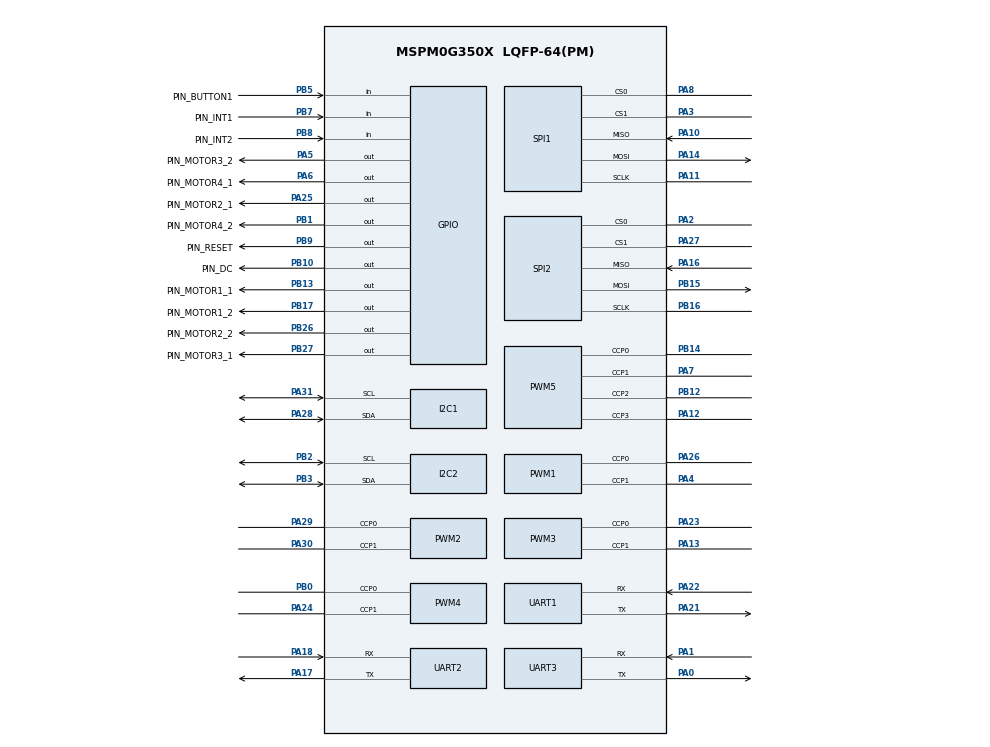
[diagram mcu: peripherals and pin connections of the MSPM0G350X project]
/**
 * @cliArgs --device "MSPM0G350X" --part "Default" --package "LQFP-64(PM)" --product "mspm0_sdk@2.03.00.07"
 * @versions {"tool":"1.22.0+3893"}
 */
scripting.excludeFromBuild("Event.dot");

/**
 * Import the modules used in this configuration.
 */
const ADC12         = scripting.addModule("/ti/driverlib/ADC12", {}, false);
const ADC121        = ADC12.addInstance();
const DMA           = scripting.addModule("/ti/driverlib/DMA");
const GPIO          = scripting.addModule("/ti/driverlib/GPIO", {}, false);
const GPIO1         = GPIO.addInstance();
const GPIO2         = GPIO.addInstance();
const GPIO3         = GPIO.addInstance();
const GPIO4         = GPIO.addInstance();
const GPIO5         = GPIO.addInstance();
const I2C           = scripting.addModule("/ti/driverlib/I2C", {}, false);
const I2C1          = I2C.addInstance();
const I2C2          = I2C.addInstance();
const PWM           = scripting.addModule("/ti/driverlib/PWM", {}, false);
const PWM1          = PWM.addInstance();
const PWM2          = PWM.addInstance();
const PWM3          = PWM.addInstance();
const PWM4          = PWM.addInstance();
const PWM5          = PWM.addInstance();
const RTC           = scripting.addModule("/ti/driverlib/RTC");
const SPI           = scripting.addModule("/ti/driverlib/SPI", {}, false);
const SPI1          = SPI.addInstance();
const SPI2          = SPI.addInstance();
const SYSCTL        = scripting.addModule("/ti/driverlib/SYSCTL");
const SYSTICK       = scripting.addModule("/ti/driverlib/SYSTICK");
const TIMER         = scripting.addModule("/ti/driverlib/TIMER", {}, false);
const TIMER1        = TIMER.addInstance();
const UART          = scripting.addModule("/ti/driverlib/UART", {}, false);
const UART1         = UART.addInstance();
const UART2         = UART.addInstance();
const UART3         = UART.addInstance();
const ProjectConfig = scripting.addModule("/ti/project_config/ProjectConfig");

/**
 * Write custom configuration values to the imported modules.
 */
ADC121.$name                      = "ADC12_0";
ADC121.peripheral.$assign         = "ADC1";
ADC121.peripheral.adcPin0.$assign = "PA15";
ADC121.adcPin0Config.$name        = "ti_driverlib_gpio_GPIOPinGeneric32";

const Board = scripting.addModule("/ti/driverlib/Board", {}, false);

GPIO1.$name                               = "GPIO_GRP_ENCODER";
GPIO1.associatedPins.create(8);
GPIO1.associatedPins[0].direction         = "INPUT";
GPIO1.associatedPins[0].ioStructure       = "SD";
GPIO1.associatedPins[0].assignedPort      = "PORTB";
GPIO1.associatedPins[0].interruptEn       = true;
GPIO1.associatedPins[0].interruptPriority = "2";
GPIO1.associatedPins[0].polarity          = "RISE_FALL";
GPIO1.associatedPins[0].$name             = "PIN_MOTOR1_A";
GPIO1.associatedPins[1].direction         = "INPUT";
GPIO1.associatedPins[1].ioStructure       = "SD";
GPIO1.associatedPins[1].assignedPort      = "PORTB";
GPIO1.associatedPins[1].interruptEn       = true;
GPIO1.associatedPins[1].polarity          = "RISE_FALL";
GPIO1.associatedPins[1].interruptPriority = "2";
GPIO1.associatedPins[1].$name             = "PIN_MOTOR1_B";
GPIO1.associatedPins[2].direction         = "INPUT";
GPIO1.associatedPins[2].ioStructure       = "SD";
GPIO1.associatedPins[2].assignedPort      = "PORTB";
GPIO1.associatedPins[2].interruptEn       = true;
GPIO1.associatedPins[2].interruptPriority = "2";
GPIO1.associatedPins[2].polarity          = "RISE_FALL";
GPIO1.associatedPins[2].$name             = "PIN_MOTOR2_A";
GPIO1.associatedPins[3].direction         = "INPUT";
GPIO1.associatedPins[3].ioStructure       = "SD";
GPIO1.associatedPins[3].interruptEn       = true;
GPIO1.associatedPins[3].interruptPriority = "2";
GPIO1.associatedPins[3].polarity          = "RISE_FALL";
GPIO1.associatedPins[3].assignedPort      = "PORTB";
GPIO1.associatedPins[3].$name             = "PIN_MOTOR2_B";
GPIO1.associatedPins[4].direction         = "INPUT";
GPIO1.associatedPins[4].ioStructure       = "SD";
GPIO1.associatedPins[4].interruptEn       = true;
GPIO1.associatedPins[4].interruptPriority = "2";
GPIO1.associatedPins[4].polarity          = "RISE_FALL";
GPIO1.associatedPins[4].assignedPort      = "PORTB";
GPIO1.associatedPins[4].$name             = "PIN_MOTOR3_A";
GPIO1.associatedPins[5].direction         = "INPUT";
GPIO1.associatedPins[5].ioStructure       = "SD";
GPIO1.associatedPins[5].interruptEn       = true;
GPIO1.associatedPins[5].polarity          = "RISE_FALL";
GPIO1.associatedPins[5].assignedPort      = "PORTB";
GPIO1.associatedPins[5].$name             = "PIN_MOTOR3_B";
GPIO1.associatedPins[6].direction         = "INPUT";
GPIO1.associatedPins[6].ioStructure       = "SD";
GPIO1.associatedPins[6].assignedPort      = "PORTB";
GPIO1.associatedPins[6].interruptEn       = true;
GPIO1.associatedPins[6].polarity          = "RISE_FALL";
GPIO1.associatedPins[6].$name             = "PIN_MOTOR4_A";
GPIO1.associatedPins[7].direction         = "INPUT";
GPIO1.associatedPins[7].ioStructure       = "SD";
GPIO1.associatedPins[7].assignedPort      = "PORTB";
GPIO1.associatedPins[7].interruptEn       = true;
GPIO1.associatedPins[7].polarity          = "RISE_FALL";
GPIO1.associatedPins[7].interruptPriority = "2";
GPIO1.associatedPins[7].$name             = "PIN_MOTOR4_B";

GPIO2.$name                          = "GPIO_GRP_MCTRL";
GPIO2.associatedPins.create(8);
GPIO2.associatedPins[0].ioStructure  = "SD";
GPIO2.associatedPins[0].initialValue = "SET";
GPIO2.associatedPins[0].$name        = "PIN_MOTOR1_1";
GPIO2.associatedPins[0].pin.$assign  = "PB13";
GPIO2.associatedPins[1].ioStructure  = "SD";
GPIO2.associatedPins[1].initialValue = "SET";
GPIO2.associatedPins[1].$name        = "PIN_MOTOR1_2";
GPIO2.associatedPins[1].pin.$assign  = "PB17";
GPIO2.associatedPins[2].initialValue = "SET";
GPIO2.associatedPins[2].$name        = "PIN_MOTOR2_1";
GPIO2.associatedPins[2].pin.$assign  = "PA25";
GPIO2.associatedPins[3].initialValue = "SET";
GPIO2.associatedPins[3].$name        = "PIN_MOTOR2_2";
GPIO2.associatedPins[3].pin.$assign  = "PB26";
GPIO2.associatedPins[4].initialValue = "SET";
GPIO2.associatedPins[4].$name        = "PIN_MOTOR3_1";
GPIO2.associatedPins[4].pin.$assign  = "PB27";
GPIO2.associatedPins[5].initialValue = "SET";
GPIO2.associatedPins[5].$name        = "PIN_MOTOR3_2";
GPIO2.associatedPins[5].pin.$assign  = "PA5";
GPIO2.associatedPins[6].initialValue = "SET";
GPIO2.associatedPins[6].$name        = "PIN_MOTOR4_1";
GPIO2.associatedPins[6].pin.$assign  = "PA6";
GPIO2.associatedPins[7].initialValue = "SET";
GPIO2.associatedPins[7].$name        = "PIN_MOTOR4_2";
GPIO2.associatedPins[7].pin.$assign  = "PB1";

GPIO3.$name                               = "GPIO_GRP_BUTTON";
GPIO3.associatedPins[0].direction         = "INPUT";
GPIO3.associatedPins[0].ioStructure       = "SD";
GPIO3.associatedPins[0].interruptEn       = true;
GPIO3.associatedPins[0].interruptPriority = "2";
GPIO3.associatedPins[0].polarity          = "FALL";
GPIO3.associatedPins[0].$name             = "PIN_BUTTON1";
GPIO3.associatedPins[0].pin.$assign       = "PB5";

GPIO4.$name                               = "GPIO_GRP_IMU_INT";
GPIO4.associatedPins.create(2);
GPIO4.associatedPins[0].$name             = "PIN_INT1";
GPIO4.associatedPins[0].direction         = "INPUT";
GPIO4.associatedPins[0].ioStructure       = "SD";
GPIO4.associatedPins[0].interruptEn       = true;
GPIO4.associatedPins[0].interruptPriority = "1";
GPIO4.associatedPins[0].polarity          = "RISE";
GPIO4.associatedPins[0].pin.$assign       = "PB7";
GPIO4.associatedPins[1].$name             = "PIN_INT2";
GPIO4.associatedPins[1].direction         = "INPUT";
GPIO4.associatedPins[1].ioStructure       = "SD";
GPIO4.associatedPins[1].interruptEn       = true;
GPIO4.associatedPins[1].interruptPriority = "1";
GPIO4.associatedPins[1].polarity          = "RISE";
GPIO4.associatedPins[1].pin.$assign       = "PB8";

GPIO5.$name                          = "GPIO_GRP_OLED";
GPIO5.associatedPins.create(2);
GPIO5.associatedPins[0].initialValue = "SET";
GPIO5.associatedPins[0].ioStructure  = "SD";
GPIO5.associatedPins[0].$name        = "PIN_RESET";
GPIO5.associatedPins[0].pin.$assign  = "PB9";
GPIO5.associatedPins[1].$name        = "PIN_DC";
GPIO5.associatedPins[1].initialValue = "SET";
GPIO5.associatedPins[1].ioStructure  = "SD";
GPIO5.associatedPins[1].pin.$assign  = "PB10";

I2C1.$name                     = "I2C_0";
I2C1.basicEnableController     = true;
I2C1.peripheral.$assign        = "I2C0";
I2C1.peripheral.sdaPin.$assign = "PA28";
I2C1.peripheral.sclPin.$assign = "PA31";
I2C1.sdaPinConfig.$name        = "ti_driverlib_gpio_GPIOPinGeneric7";
I2C1.sclPinConfig.$name        = "ti_driverlib_gpio_GPIOPinGeneric8";

I2C2.$name                     = "I2C_1";
I2C2.peripheral.$assign        = "I2C1";
I2C2.peripheral.sdaPin.$assign = "PB3";
I2C2.peripheral.sclPin.$assign = "PB2";
I2C2.sdaPinConfig.$name        = "ti_driverlib_gpio_GPIOPinGeneric19";
I2C2.sclPinConfig.$name        = "ti_driverlib_gpio_GPIOPinGeneric20";

PWM1.pwmMode                            = "EDGE_ALIGN_UP";
PWM1.timerStartTimer                    = true;
PWM1.$name                              = "PWM_MOTOR_12";
PWM1.peripheral.$assign                 = "TIMG7";
PWM1.peripheral.ccp0Pin.$assign         = "PA26";
PWM1.peripheral.ccp1Pin.$assign         = "PA4";
PWM1.PWM_CHANNEL_0.$name                = "ti_driverlib_pwm_PWMTimerCC0";
PWM1.PWM_CHANNEL_1.$name                = "ti_driverlib_pwm_PWMTimerCC1";
PWM1.ccp0PinConfig.direction            = scripting.forceWrite("OUTPUT");
PWM1.ccp0PinConfig.hideOutputInversion  = scripting.forceWrite(false);
PWM1.ccp0PinConfig.onlyInternalResistor = scripting.forceWrite(false);
PWM1.ccp0PinConfig.passedPeripheralType = scripting.forceWrite("Digital");
PWM1.ccp0PinConfig.$name                = "ti_driverlib_gpio_GPIOPinGeneric21";
PWM1.ccp1PinConfig.direction            = scripting.forceWrite("OUTPUT");
PWM1.ccp1PinConfig.hideOutputInversion  = scripting.forceWrite(false);
PWM1.ccp1PinConfig.onlyInternalResistor = scripting.forceWrite(false);
PWM1.ccp1PinConfig.passedPeripheralType = scripting.forceWrite("Digital");
PWM1.ccp1PinConfig.$name                = "ti_driverlib_gpio_GPIOPinGeneric22";

PWM2.pwmMode                            = "EDGE_ALIGN_UP";
PWM2.timerStartTimer                    = true;
PWM2.$name                              = "PWM_MOTOR_34";
PWM2.peripheral.$assign                 = "TIMG6";
PWM2.peripheral.ccp0Pin.$assign         = "PA29";
PWM2.peripheral.ccp1Pin.$assign         = "PA30";
PWM2.PWM_CHANNEL_0.$name                = "ti_driverlib_pwm_PWMTimerCC2";
PWM2.PWM_CHANNEL_1.$name                = "ti_driverlib_pwm_PWMTimerCC3";
PWM2.ccp0PinConfig.direction            = scripting.forceWrite("OUTPUT");
PWM2.ccp0PinConfig.hideOutputInversion  = scripting.forceWrite(false);
PWM2.ccp0PinConfig.onlyInternalResistor = scripting.forceWrite(false);
PWM2.ccp0PinConfig.passedPeripheralType = scripting.forceWrite("Digital");
PWM2.ccp0PinConfig.$name                = "ti_driverlib_gpio_GPIOPinGeneric23";
PWM2.ccp1PinConfig.direction            = scripting.forceWrite("OUTPUT");
PWM2.ccp1PinConfig.hideOutputInversion  = scripting.forceWrite(false);
PWM2.ccp1PinConfig.onlyInternalResistor = scripting.forceWrite(false);
PWM2.ccp1PinConfig.passedPeripheralType = scripting.forceWrite("Digital");
PWM2.ccp1PinConfig.$name                = "ti_driverlib_gpio_GPIOPinGeneric24";

PWM3.timerStartTimer                    = true;
PWM3.pwmMode                            = "EDGE_ALIGN_UP";
PWM3.$name                              = "PWM_0";
PWM3.peripheral.$assign                 = "TIMG0";
PWM3.peripheral.ccp0Pin.$assign         = "PA23";
PWM3.peripheral.ccp1Pin.$assign         = "PA13";
PWM3.PWM_CHANNEL_0.$name                = "ti_driverlib_pwm_PWMTimerCC4";
PWM3.PWM_CHANNEL_1.$name                = "ti_driverlib_pwm_PWMTimerCC5";
PWM3.PWM_CHANNEL_1.initVal              = "HIGH";
PWM3.ccp0PinConfig.direction            = scripting.forceWrite("OUTPUT");
PWM3.ccp0PinConfig.hideOutputInversion  = scripting.forceWrite(false);
PWM3.ccp0PinConfig.onlyInternalResistor = scripting.forceWrite(false);
PWM3.ccp0PinConfig.passedPeripheralType = scripting.forceWrite("Digital");
PWM3.ccp0PinConfig.$name                = "ti_driverlib_gpio_GPIOPinGeneric25";
PWM3.ccp1PinConfig.direction            = scripting.forceWrite("OUTPUT");
PWM3.ccp1PinConfig.hideOutputInversion  = scripting.forceWrite(false);
PWM3.ccp1PinConfig.onlyInternalResistor = scripting.forceWrite(false);
PWM3.ccp1PinConfig.passedPeripheralType = scripting.forceWrite("Digital");
PWM3.ccp1PinConfig.$name                = "ti_driverlib_gpio_GPIOPinGeneric26";

PWM4.timerStartTimer                    = true;
PWM4.pwmMode                            = "EDGE_ALIGN_UP";
PWM4.$name                              = "PWM_1";
PWM4.peripheral.$assign                 = "TIMA1";
PWM4.peripheral.ccp0Pin.$assign         = "PB0";
PWM4.peripheral.ccp1Pin.$assign         = "PA24";
PWM4.PWM_CHANNEL_0.$name                = "ti_driverlib_pwm_PWMTimerCC6";
PWM4.PWM_CHANNEL_0.initVal              = "HIGH";
PWM4.PWM_CHANNEL_1.$name                = "ti_driverlib_pwm_PWMTimerCC7";
PWM4.PWM_CHANNEL_1.initVal              = "HIGH";
PWM4.ccp0PinConfig.direction            = scripting.forceWrite("OUTPUT");
PWM4.ccp0PinConfig.hideOutputInversion  = scripting.forceWrite(false);
PWM4.ccp0PinConfig.onlyInternalResistor = scripting.forceWrite(false);
PWM4.ccp0PinConfig.passedPeripheralType = scripting.forceWrite("Digital");
PWM4.ccp0PinConfig.$name                = "ti_driverlib_gpio_GPIOPinGeneric27";
PWM4.ccp1PinConfig.direction            = scripting.forceWrite("OUTPUT");
PWM4.ccp1PinConfig.hideOutputInversion  = scripting.forceWrite(false);
PWM4.ccp1PinConfig.onlyInternalResistor = scripting.forceWrite(false);
PWM4.ccp1PinConfig.passedPeripheralType = scripting.forceWrite("Digital");
PWM4.ccp1PinConfig.$name                = "ti_driverlib_gpio_GPIOPinGeneric28";

PWM5.pwmMode                            = "EDGE_ALIGN_UP";
PWM5.ccIndex                            = [0,1,2,3];
PWM5.$name                              = "PWM_SERVO";
PWM5.peripheral.$assign                 = "TIMA0";
PWM5.peripheral.ccp0Pin.$assign         = "PB14";
PWM5.peripheral.ccp1Pin.$assign         = "PA7";
PWM5.peripheral.ccp2Pin.$assign         = "PB12";
PWM5.peripheral.ccp3Pin.$assign         = "PA12";
PWM5.PWM_CHANNEL_0.$name                = "ti_driverlib_pwm_PWMTimerCC8";
PWM5.PWM_CHANNEL_1.$name                = "ti_driverlib_pwm_PWMTimerCC9";
PWM5.ccp0PinConfig.direction            = scripting.forceWrite("OUTPUT");
PWM5.ccp0PinConfig.hideOutputInversion  = scripting.forceWrite(false);
PWM5.ccp0PinConfig.onlyInternalResistor = scripting.forceWrite(false);
PWM5.ccp0PinConfig.passedPeripheralType = scripting.forceWrite("Digital");
PWM5.ccp0PinConfig.$name                = "ti_driverlib_gpio_GPIOPinGeneric0";
PWM5.ccp1PinConfig.direction            = scripting.forceWrite("OUTPUT");
PWM5.ccp1PinConfig.hideOutputInversion  = scripting.forceWrite(false);
PWM5.ccp1PinConfig.onlyInternalResistor = scripting.forceWrite(false);
PWM5.ccp1PinConfig.passedPeripheralType = scripting.forceWrite("Digital");
PWM5.ccp1PinConfig.$name                = "ti_driverlib_gpio_GPIOPinGeneric1";
PWM5.PWM_CHANNEL_2.$name                = "ti_driverlib_pwm_PWMTimerCC10";
PWM5.PWM_CHANNEL_3.$name                = "ti_driverlib_pwm_PWMTimerCC11";
PWM5.ccp2PinConfig.direction            = scripting.forceWrite("OUTPUT");
PWM5.ccp2PinConfig.hideOutputInversion  = scripting.forceWrite(false);
PWM5.ccp2PinConfig.onlyInternalResistor = scripting.forceWrite(false);
PWM5.ccp2PinConfig.passedPeripheralType = scripting.forceWrite("Digital");
PWM5.ccp2PinConfig.$name                = "ti_driverlib_gpio_GPIOPinGeneric2";
PWM5.ccp3PinConfig.direction            = scripting.forceWrite("OUTPUT");
PWM5.ccp3PinConfig.hideOutputInversion  = scripting.forceWrite(false);
PWM5.ccp3PinConfig.onlyInternalResistor = scripting.forceWrite(false);
PWM5.ccp3PinConfig.passedPeripheralType = scripting.forceWrite("Digital");
PWM5.ccp3PinConfig.$name                = "ti_driverlib_gpio_GPIOPinGeneric29";

RTC.calYear = 2025;
RTC.calDOW  = "3";

SPI1.$name                          = "SPI_0";
SPI1.rxFifoThreshold                = "DL_SPI_RX_FIFO_LEVEL_ONE_FRAME";
SPI1.txFifoThreshold                = "DL_SPI_TX_FIFO_LEVEL_ONE_FRAME";
SPI1.chipSelect                     = ["0","1"];
SPI1.targetBitRate                  = 1000000;
SPI1.peripheral.$assign             = "SPI0";
SPI1.peripheral.sclkPin.$assign     = "PA11";
SPI1.peripheral.mosiPin.$assign     = "PA14";
SPI1.peripheral.misoPin.$assign     = "PA10";
SPI1.peripheral.cs0Pin.$assign      = "PA8";
SPI1.peripheral.cs1Pin.$assign      = "PA3";
SPI1.sclkPinConfig.$name            = "ti_driverlib_gpio_GPIOPinGeneric3";
SPI1.mosiPinConfig.$name            = "ti_driverlib_gpio_GPIOPinGeneric4";
SPI1.misoPinConfig.$name            = "ti_driverlib_gpio_GPIOPinGeneric5";
SPI1.misoPinConfig.enableConfig     = true;
SPI1.misoPinConfig.internalResistor = "PULL_UP";
SPI1.cs0PinConfig.$name             = "ti_driverlib_gpio_GPIOPinGeneric6";
SPI1.cs1PinConfig.$name             = "ti_driverlib_gpio_GPIOPinGeneric30";

SPI2.$name                      = "SPI_1";
SPI2.chipSelect                 = ["0","1"];
SPI2.peripheral.$assign         = "SPI1";
SPI2.peripheral.sclkPin.$assign = "PB16";
SPI2.peripheral.mosiPin.$assign = "PB15";
SPI2.peripheral.misoPin.$assign = "PA16";
SPI2.peripheral.cs0Pin.$assign  = "PA2";
SPI2.peripheral.cs1Pin.$assign  = "PA27";
SPI2.sclkPinConfig.$name        = "ti_driverlib_gpio_GPIOPinGeneric15";
SPI2.mosiPinConfig.$name        = "ti_driverlib_gpio_GPIOPinGeneric16";
SPI2.misoPinConfig.$name        = "ti_driverlib_gpio_GPIOPinGeneric17";
SPI2.cs0PinConfig.$name         = "ti_driverlib_gpio_GPIOPinGeneric18";
SPI2.cs1PinConfig.$name         = "ti_driverlib_gpio_GPIOPinGeneric31";

SYSCTL.clockTreeEn = true;

TIMER1.timerMode          = "PERIODIC_UP";
TIMER1.timerStartTimer    = true;
TIMER1.timerClkDiv        = 4;
TIMER1.$name              = "TIMER_ENCODER";
TIMER1.interrupts         = ["OVERFLOW"];
TIMER1.interruptPriority  = "2";
TIMER1.timerPeriod        = "0";
TIMER1.peripheral.$assign = "TIMG12";

UART1.$name                            = "UART_2";
UART1.targetBaudRate                   = 921600;
UART1.rxFifoThreshold                  = "DL_UART_RX_FIFO_LEVEL_ONE_ENTRY";
UART1.txFifoThreshold                  = "DL_UART_TX_FIFO_LEVEL_ONE_ENTRY";
UART1.enableFIFO                       = true;
UART1.enabledDMARXTriggers             = "DL_UART_DMA_INTERRUPT_RX";
UART1.enabledDMATXTriggers             = "DL_UART_DMA_INTERRUPT_TX";
UART1.peripheral.$assign               = "UART2";
UART1.peripheral.rxPin.$assign         = "PA22";
UART1.peripheral.txPin.$assign         = "PA21";
UART1.txPinConfig.direction            = scripting.forceWrite("OUTPUT");
UART1.txPinConfig.hideOutputInversion  = scripting.forceWrite(false);
UART1.txPinConfig.onlyInternalResistor = scripting.forceWrite(false);
UART1.txPinConfig.passedPeripheralType = scripting.forceWrite("Digital");
UART1.txPinConfig.$name                = "ti_driverlib_gpio_GPIOPinGeneric9";
UART1.rxPinConfig.hideOutputInversion  = scripting.forceWrite(false);
UART1.rxPinConfig.onlyInternalResistor = scripting.forceWrite(false);
UART1.rxPinConfig.passedPeripheralType = scripting.forceWrite("Digital");
UART1.rxPinConfig.$name                = "ti_driverlib_gpio_GPIOPinGeneric10";
UART1.DMA_CHANNEL_RX.$name             = "DMA_UART2_RX";
UART1.DMA_CHANNEL_RX.addressMode       = "f2b";
UART1.DMA_CHANNEL_RX.srcLength         = "BYTE";
UART1.DMA_CHANNEL_RX.dstLength         = "BYTE";
UART1.DMA_CHANNEL_TX.$name             = "DMA_UART2_TX";
UART1.DMA_CHANNEL_TX.addressMode       = "b2f";
UART1.DMA_CHANNEL_TX.srcLength         = "BYTE";
UART1.DMA_CHANNEL_TX.dstLength         = "BYTE";

UART2.$name                        = "UART_1";
UART2.targetBaudRate               = 921600;
UART2.enabledDMARXTriggers         = "DL_UART_DMA_INTERRUPT_RX";
UART2.enabledDMATXTriggers         = "DL_UART_DMA_INTERRUPT_TX";
UART2.enabledInterrupts            = ["DMA_DONE_RX","DMA_DONE_TX","EOT_DONE"];
UART2.peripheral.$assign           = "UART1";
UART2.peripheral.rxPin.$assign     = "PA18";
UART2.peripheral.txPin.$assign     = "PA17";
UART2.txPinConfig.$name            = "ti_driverlib_gpio_GPIOPinGeneric11";
UART2.rxPinConfig.$name            = "ti_driverlib_gpio_GPIOPinGeneric12";
UART2.rxPinConfig.internalResistor = "PULL_DOWN";
UART2.DMA_CHANNEL_RX.$name         = "DMA_UART1_RX";
UART2.DMA_CHANNEL_RX.addressMode   = "f2b";
UART2.DMA_CHANNEL_RX.srcLength     = "BYTE";
UART2.DMA_CHANNEL_RX.dstLength     = "BYTE";
UART2.DMA_CHANNEL_TX.$name         = "DMA_UART1_TX";
UART2.DMA_CHANNEL_TX.addressMode   = "b2f";
UART2.DMA_CHANNEL_TX.srcLength     = "BYTE";
UART2.DMA_CHANNEL_TX.dstLength     = "BYTE";

UART3.$name                            = "UART_0";
UART3.targetBaudRate                   = 921600;
UART3.enabledDMARXTriggers             = "DL_UART_DMA_INTERRUPT_RX";
UART3.enabledDMATXTriggers             = "DL_UART_DMA_INTERRUPT_TX";
UART3.enableFIFO                       = true;
UART3.rxFifoThreshold                  = "DL_UART_RX_FIFO_LEVEL_ONE_ENTRY";
UART3.txFifoThreshold                  = "DL_UART_TX_FIFO_LEVEL_ONE_ENTRY";
UART3.enabledInterrupts                = ["DMA_DONE_RX","DMA_DONE_TX","EOT_DONE"];
UART3.peripheral.$assign               = "UART0";
UART3.peripheral.rxPin.$assign         = "PA1";
UART3.peripheral.txPin.$assign         = "PA0";
UART3.txPinConfig.direction            = scripting.forceWrite("OUTPUT");
UART3.txPinConfig.hideOutputInversion  = scripting.forceWrite(false);
UART3.txPinConfig.onlyInternalResistor = scripting.forceWrite(false);
UART3.txPinConfig.passedPeripheralType = scripting.forceWrite("Digital");
UART3.txPinConfig.$name                = "ti_driverlib_gpio_GPIOPinGeneric13";
UART3.rxPinConfig.hideOutputInversion  = scripting.forceWrite(false);
UART3.rxPinConfig.onlyInternalResistor = scripting.forceWrite(false);
UART3.rxPinConfig.passedPeripheralType = scripting.forceWrite("Digital");
UART3.rxPinConfig.$name                = "ti_driverlib_gpio_GPIOPinGeneric14";
UART3.DMA_CHANNEL_RX.$name             = "DMA_UART0_RX";
UART3.DMA_CHANNEL_RX.srcLength         = "BYTE";
UART3.DMA_CHANNEL_RX.dstLength         = "BYTE";
UART3.DMA_CHANNEL_RX.addressMode       = "f2b";
UART3.DMA_CHANNEL_TX.$name             = "DMA_UART0_TX";
UART3.DMA_CHANNEL_TX.srcLength         = "BYTE";
UART3.DMA_CHANNEL_TX.dstLength         = "BYTE";
UART3.DMA_CHANNEL_TX.addressMode       = "b2f";

ProjectConfig.genLibCMSIS = true;

/**
 * Pinmux solution for unlocked pins/peripherals. This ensures that minor changes to the automatic solver in a future
 * version of the tool will not impact the pinmux you originally saw.  These lines can be completely deleted in order to
 * re-solve from scratch.
 */
Board.peripheral.$suggestSolution                = "DEBUGSS";
Board.peripheral.swclkPin.$suggestSolution       = "PA20";
Board.peripheral.swdioPin.$suggestSolution       = "PA19";
GPIO1.associatedPins[0].pin.$suggestSolution     = "PB25";
GPIO1.associatedPins[1].pin.$suggestSolution     = "PB24";
GPIO1.associatedPins[2].pin.$suggestSolution     = "PB23";
GPIO1.associatedPins[3].pin.$suggestSolution     = "PB22";
GPIO1.associatedPins[4].pin.$suggestSolution     = "PB21";
GPIO1.associatedPins[5].pin.$suggestSolution     = "PB20";
GPIO1.associatedPins[6].pin.$suggestSolution     = "PB19";
GPIO1.associatedPins[7].pin.$suggestSolution     = "PB18";
RTC.peripheral.$suggestSolution                  = "RTC";
UART1.DMA_CHANNEL_RX.peripheral.$suggestSolution = "DMA_CH5";
UART1.DMA_CHANNEL_TX.peripheral.$suggestSolution = "DMA_CH4";
UART2.DMA_CHANNEL_RX.peripheral.$suggestSolution = "DMA_CH3";
UART2.DMA_CHANNEL_TX.peripheral.$suggestSolution = "DMA_CH2";
UART3.DMA_CHANNEL_RX.peripheral.$suggestSolution = "DMA_CH1";
UART3.DMA_CHANNEL_TX.peripheral.$suggestSolution = "DMA_CH0";
